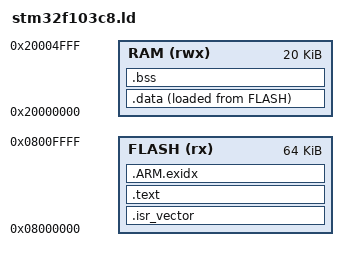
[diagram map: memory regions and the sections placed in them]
/*
 * 砾（LI）STM32F103C8T6 链接脚本
 * Flash 64 KB / RAM 20 KB（按标称容量保守配置）
 */

ENTRY(Reset_Handler)

MEMORY
{
    FLASH (rx)  : ORIGIN = 0x08000000, LENGTH = 64K
    RAM   (rwx) : ORIGIN = 0x20000000, LENGTH = 20K
}

/* 栈顶：RAM 末尾，向低地址生长 */
_estack = ORIGIN(RAM) + LENGTH(RAM);

/* 至少给主栈保留的字节数 */
_Min_Stack_Size = 0x800;

SECTIONS
{
    .isr_vector :
    {
        . = ALIGN(4);
        KEEP(*(.isr_vector))
        . = ALIGN(4);
    } > FLASH

    .text :
    {
        . = ALIGN(4);
        *(.text*)
        *(.rodata*)
        *(.glue_7)
        *(.glue_7t)
        . = ALIGN(4);
    } > FLASH

    .ARM.exidx :
    {
        . = ALIGN(4);
        *(.ARM.exidx*)
        . = ALIGN(4);
    } > FLASH

    .data :
    {
        . = ALIGN(4);
        _sdata = .;
        *(.data*)
        . = ALIGN(4);
        _edata = .;
    } > RAM AT> FLASH
    _sidata = LOADADDR(.data);

    .bss (NOLOAD) :
    {
        . = ALIGN(4);
        _sbss = .;
        __bss_start__ = _sbss;
        *(.bss*)
        *(COMMON)
        . = ALIGN(4);
        _ebss = .;
        __bss_end__ = _ebss;
    } > RAM

    ASSERT(_ebss <= (_estack - _Min_Stack_Size), "RAM 溢出：留给主栈的空间不足 2 KB")
}
